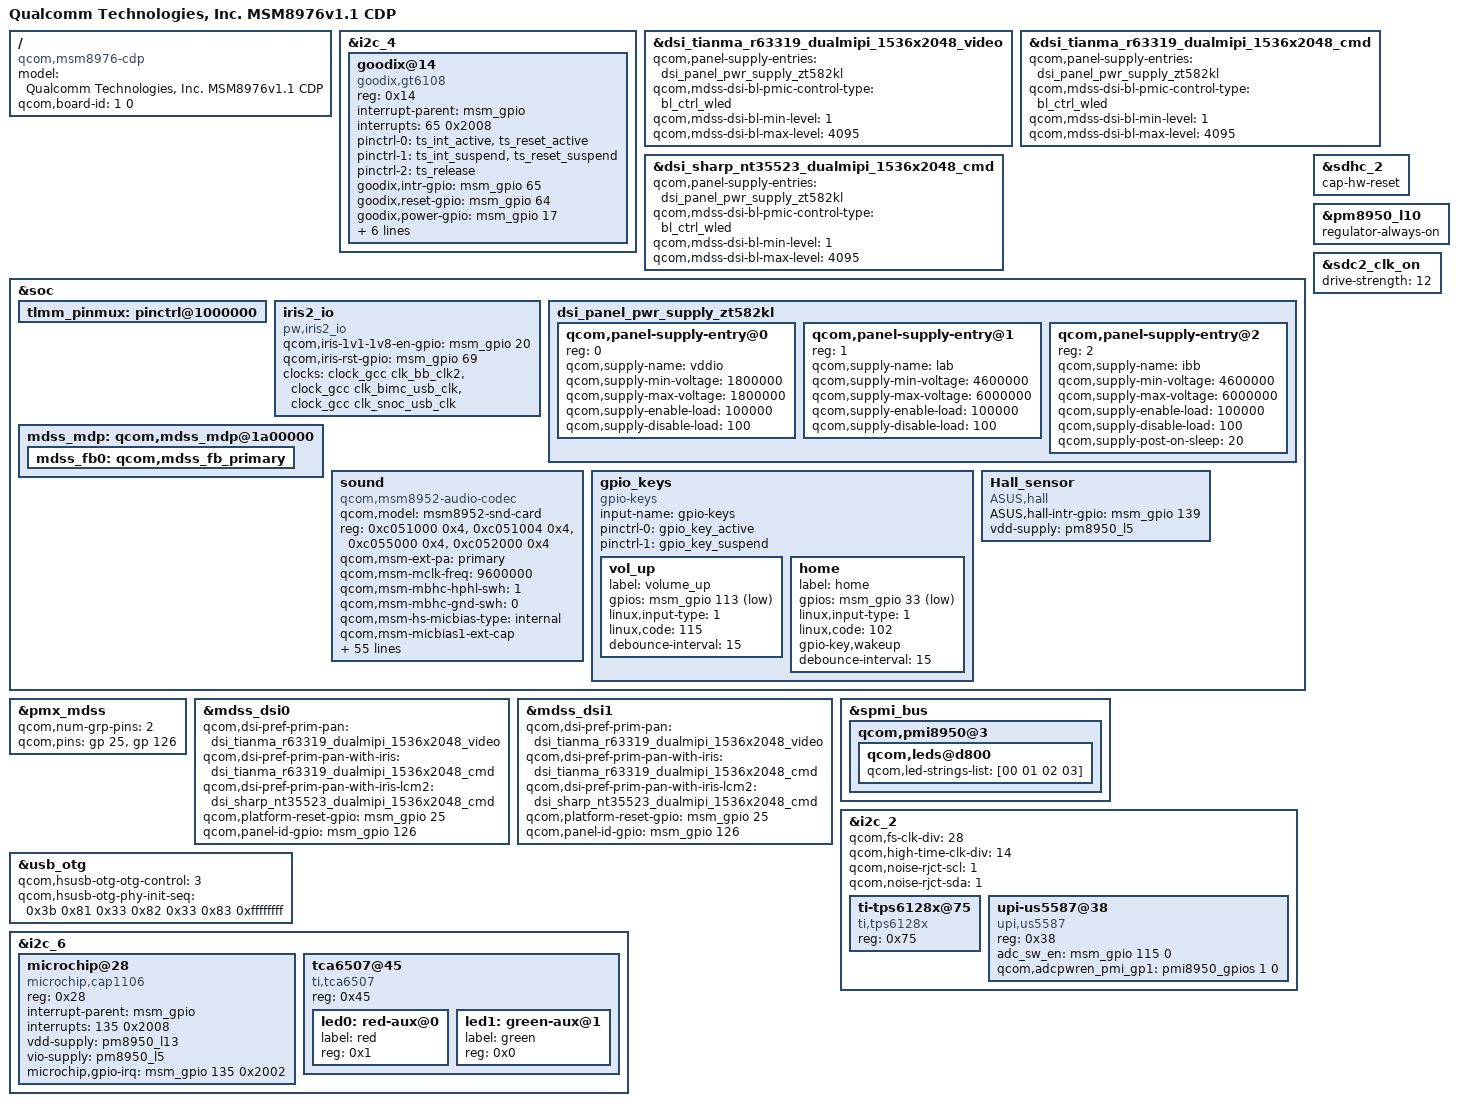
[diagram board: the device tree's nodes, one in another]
/*
 * Copyright (c) 2015, The Linux Foundation. All rights reserved.
 *
 * This program is free software; you can redistribute it and/or modify
 * it under the terms of the GNU General Public License version 2 and
 * only version 2 as published by the Free Software Foundation.
 *
 * This program is distributed in the hope that it will be useful,
 * but WITHOUT ANY WARRANTY; without even the implied warranty of
 * MERCHANTABILITY or FITNESS FOR A PARTICULAR PURPOSE.  See the
 * GNU General Public License for more details.
 */

/dts-v1/;

#include "msm8976-v1.1.dtsi"
#include "msm8976-cdp.dtsi"
#include "msm8976-camera-sensor-cdp-ZT582KL.dtsi"

/ {
	model = "Qualcomm Technologies, Inc. MSM8976v1.1 CDP";
	compatible = "qcom,msm8976-cdp", "qcom,msm8976", "qcom,cdp";
	qcom,board-id= <1 0>;
};

&i2c_4 { /* BLSP1 QUP4 */
	goodix@14 {
 		compatible = "goodix,gt6108";
		reg = <0x14>;
		interrupt-parent = <&msm_gpio>;
		interrupts = <65 0x2008>;
//		vdd-supply = <&pm8916_l17>;
//		vcc_i2c-supply = <&pm8916_l6>;
		/* pins used by touchscreen */
		pinctrl-names = "gt6108_init_default","gt6108_init_suspend";
		pinctrl-0 = <&ts_int_active &ts_reset_active>;
		pinctrl-1 = <&ts_int_suspend &ts_reset_suspend>;
		pinctrl-2 = <&ts_release>;
		goodix,intr-gpio = <&msm_gpio 65 0x2008>;
		goodix,reset-gpio = <&msm_gpio 64 0x0>;
		goodix,power-gpio = <&msm_gpio 17 0x0>;
		goodix,fw-name = "GD_Upgrade_App.i";
		goodix,display-coords = <0 0 1536 2048>;
		goodix,panel-coords = <0 0 1080 2000>;
		goodix,button-map= <70 150 907>;
		goodix,product-id = <6108>;
		goodix,i2c-pull-up;
	};
};

/* DISPLAY START*/

#include "dsi-panel-tianma-r63319-dualmipi-1536x2048-video.dtsi"
#include "dsi-panel-tianma-r63319-dualmipi-1536x2048-cmd.dtsi"
#include "dsi-panel-sharp-nt35523-dualmipi-1536x2048-cmd.dtsi"

&dsi_tianma_r63319_dualmipi_1536x2048_video {
/*  qcom,panel-supply-entries = <&dsi_panel_pwr_supply>;*/
    qcom,panel-supply-entries = <&dsi_panel_pwr_supply_zt582kl>;
    qcom,mdss-dsi-bl-pmic-control-type = "bl_ctrl_wled";
    qcom,mdss-dsi-bl-min-level = <1>;
    qcom,mdss-dsi-bl-max-level = <4095>;
/*  qcom,mdss-dsi-pan-enable-dynamic-fps;*/
/*  qcom,mdss-dsi-pan-fps-update = "dfps_immediate_porch_mode_hfp";*/
};

&dsi_tianma_r63319_dualmipi_1536x2048_cmd {
/*  qcom,panel-supply-entries = <&dsi_panel_pwr_supply>;*/
qcom,panel-supply-entries = <&dsi_panel_pwr_supply_zt582kl>;
qcom,mdss-dsi-bl-pmic-control-type = "bl_ctrl_wled";
qcom,mdss-dsi-bl-min-level = <1>;
qcom,mdss-dsi-bl-max-level = <4095>;
/*  qcom,mdss-dsi-pan-enable-dynamic-fps;*/
/*  qcom,mdss-dsi-pan-fps-update = "dfps_immediate_porch_mode_hfp";*/
};

&dsi_sharp_nt35523_dualmipi_1536x2048_cmd {
/*  qcom,panel-supply-entries = <&dsi_panel_pwr_supply>;*/
qcom,panel-supply-entries = <&dsi_panel_pwr_supply_zt582kl>;
qcom,mdss-dsi-bl-pmic-control-type = "bl_ctrl_wled";
qcom,mdss-dsi-bl-min-level = <1>;
qcom,mdss-dsi-bl-max-level = <4095>;
/*  qcom,mdss-dsi-pan-enable-dynamic-fps;*/
/*  qcom,mdss-dsi-pan-fps-update = "dfps_immediate_porch_mode_hfp";*/
};

&soc {
    tlmm_pinmux: pinctrl@1000000 {
        /delete-node/ pmx_nfc_reset;
        /delete-node/ tpiu_seta_14;
    };
};

&soc {
    iris2_io{
	 compatible = "pw,iris2_io";
	 qcom,iris-1v1-1v8-en-gpio = <&msm_gpio 20 0>;
	 qcom,iris-rst-gpio = <&msm_gpio 69 0>;
	 clocks = <&clock_gcc clk_bb_clk2>, <&clock_gcc clk_bimc_usb_clk>, <&clock_gcc clk_snoc_usb_clk>;
	 clock-names = "iris2_clk", "bimc_clk", "snoc_clk";
    };
};

&pmx_mdss {
    qcom,num-grp-pins = <2>;
    qcom,pins = <&gp 25>, <&gp 126>;
};

&mdss_dsi0 {
    qcom,dsi-pref-prim-pan = <&dsi_tianma_r63319_dualmipi_1536x2048_video>;
    qcom,dsi-pref-prim-pan-with-iris = <&dsi_tianma_r63319_dualmipi_1536x2048_cmd>;
    qcom,dsi-pref-prim-pan-with-iris-lcm2 = <&dsi_sharp_nt35523_dualmipi_1536x2048_cmd>;

    qcom,platform-reset-gpio = <&msm_gpio 25 0>;
    /delete-property/ qcom,platform-bklight-en-gpio;
    /delete-property/ qcom,panel-mode-gpio;
    qcom,panel-id-gpio = <&msm_gpio 126 0>;
};

&mdss_dsi1 {
    qcom,dsi-pref-prim-pan = <&dsi_tianma_r63319_dualmipi_1536x2048_video>;
    qcom,dsi-pref-prim-pan-with-iris = <&dsi_tianma_r63319_dualmipi_1536x2048_cmd>;
    qcom,dsi-pref-prim-pan-with-iris-lcm2 = <&dsi_sharp_nt35523_dualmipi_1536x2048_cmd>;

    qcom,platform-reset-gpio = <&msm_gpio 25 0>;
    /delete-property/ qcom,platform-bklight-en-gpio;
    /delete-property/ qcom,panel-mode-gpio;
    qcom,panel-id-gpio = <&msm_gpio 126 0>;
};

&spmi_bus{
    qcom,pmi8950@3 {
        qcom,leds@d800 {
            qcom,led-strings-list = [00 01 02 03];
        };
    };
};

&soc {
    dsi_panel_pwr_supply_zt582kl: dsi_panel_pwr_supply_zt582kl {
        #address-cells = <1>;
        #size-cells = <0>;

        qcom,panel-supply-entry@0 {
            reg = <0>;
            qcom,supply-name = "vddio";
            qcom,supply-min-voltage = <1800000>;
            qcom,supply-max-voltage = <1800000>;
            qcom,supply-enable-load = <100000>;
            qcom,supply-disable-load = <100>;
        };

        qcom,panel-supply-entry@1 {
            reg = <1>;
            qcom,supply-name = "lab";
            qcom,supply-min-voltage = <4600000>;
            qcom,supply-max-voltage = <6000000>;
            qcom,supply-enable-load = <100000>;
            qcom,supply-disable-load = <100>;
        };

        qcom,panel-supply-entry@2 {
            reg = <2>;
            qcom,supply-name = "ibb";
            qcom,supply-min-voltage = <4600000>;
            qcom,supply-max-voltage = <6000000>;
            qcom,supply-enable-load = <100000>;
            qcom,supply-disable-load = <100>;
            qcom,supply-post-on-sleep = <20>;
        };
    };

    mdss_mdp: qcom,mdss_mdp@1a00000 {
        mdss_fb0: qcom,mdss_fb_primary {
            /delete-property/ qcom,mdss-fb-splash-logo-enabled;
        };
    };
};

/* DISPLAY END*/

/* USB Start */
&i2c_2 {
       /* Override FS and HS divider to get SCL running at 400KHz. */
       qcom,fs-clk-div = <28>;
       qcom,high-time-clk-div = <14>;
       qcom,noise-rjct-scl = <1>;
       qcom,noise-rjct-sda = <1>;

       #include "rt1711-ZT582KL.dts"

    ti-tps6128x@75 {
        compatible = "ti,tps6128x";
        reg = <0x75>;
    };

    upi-us5587@38 {
        compatible = "upi,us5587";
        reg = <0x38>;
        adc_sw_en = <&msm_gpio 115 0>;
	 /*shilun*/
        qcom,adcpwren_pmi_gp1 = <&pmi8950_gpios 1 0>;
    };
};

&soc {
    /* delete unused node avoid use same gpio 19 for cc enb pin*/
    /delete-node/ pmx_i2c_8;
};

&usb_otg {
	 qcom,hsusb-otg-otg-control = <3>; /* USER control */
         qcom,hsusb-otg-phy-init-seq =
             <0x3b 0x81 0x33 0x82 0x33 0x83 0xffffffff>;
};

/* USB End */

/* AUDIO Start */

&soc {
    sound {
        compatible = "qcom,msm8952-audio-codec";
        qcom,model = "msm8952-snd-card";
        reg = <0xc051000 0x4>,
              <0xc051004 0x4>,
              <0xc055000 0x4>,
              <0xc052000 0x4>;
        reg-names = "csr_gp_io_mux_mic_ctl",
                    "csr_gp_io_mux_spkr_ctl",
                    "csr_gp_io_lpaif_pri_pcm_pri_mode_muxsel",
                    "csr_gp_io_mux_quin_ctl";

        qcom,msm-ext-pa = "primary";
        qcom,msm-mclk-freq = <9600000>;
        qcom,msm-mbhc-hphl-swh = <1>;
        qcom,msm-mbhc-gnd-swh = <0>;
        qcom,msm-hs-micbias-type = "internal";
        qcom,msm-micbias1-ext-cap;
        qcom,msm-micbias2-ext-cap;
        qcom,audio-routing =
                "RX_BIAS", "MCLK",
                "SPK_RX_BIAS", "MCLK",
                "INT_LDO_H", "MCLK",
                "MIC BIAS Internal1", "Handset Mic",
                "MIC BIAS Internal2", "Headset Mic",
                "MIC BIAS External", "Secondary Mic",
                "AMIC1", "MIC BIAS Internal1",
                "AMIC2", "MIC BIAS Internal2",
                "AMIC3", "MIC BIAS External",
		"DMIC1", "MIC BIAS Internal1",
                "MIC BIAS Internal1", "Digital Mic1",
                "DMIC2", "MIC BIAS Internal1",
                "MIC BIAS Internal1", "Digital Mic2",
                "WSA_SPK OUT", "VDD_WSA_SWITCH",
                "SpkrMono WSA_IN", "WSA_SPK OUT";
        qcom,msm-gpios =
                "pri_i2s";
        qcom,pinctrl-names =
                "all_off",
                "pri_i2s_act";
        pinctrl-names =
                "all_off",
                "pri_i2s_act";
        pinctrl-0 = <&cdc_pdm_lines_sus &cdc_pdm_lines_2_sus>;
        pinctrl-1 = <&cdc_pdm_lines_act &cdc_pdm_lines_2_act>;
        asoc-platform = <&pcm0>, <&pcm1>, <&pcm2>, <&voip>, <&voice>,
                        <&loopback>, <&compress>, <&hostless>,
                        <&afe>, <&lsm>, <&routing>, <&lpa>,
                        <&voice_svc>;
        asoc-platform-names = "msm-pcm-dsp.0", "msm-pcm-dsp.1",
                        "msm-pcm-dsp.2", "msm-voip-dsp",
                        "msm-pcm-voice", "msm-pcm-loopback",
                        "msm-compress-dsp", "msm-pcm-hostless",
                        "msm-pcm-afe", "msm-lsm-client",
                        "msm-pcm-routing", "msm-pcm-lpa",
                        "msm-voice-svc";
        asoc-cpu = <&dai_pri_auxpcm>, <&dai_hdmi>,
                        <&dai_mi2s0>, <&dai_mi2s1>, <&dai_mi2s2>,
                        <&dai_mi2s3>, <&dai_mi2s5>, <&dai_mi2s6>,
                        <&bt_sco_rx>, <&bt_sco_tx>, <&int_fm_rx>,
                        <&int_fm_tx>, <&afe_pcm_rx>, <&afe_pcm_tx>,
                        <&afe_proxy_rx>, <&afe_proxy_tx>,
                        <&incall_record_rx>, <&incall_record_tx>,
                        <&incall_music_rx>, <&incall_music_2_rx>;
        asoc-cpu-names = "msm-dai-q6-auxpcm.1", "msm-dai-q6-hdmi.8",
                        "msm-dai-q6-mi2s.0", "msm-dai-q6-mi2s.1",
                        "msm-dai-q6-mi2s.2", "msm-dai-q6-mi2s.3",
                        "msm-dai-q6-mi2s.5", "msm-dai-q6-mi2s.6",
                        /*
                        "msm-dai-q6-dev.16384", "msm-dai-q6-dev.16385",
                        "msm-dai-q6-dev.16386", "msm-dai-q6-dev.16387",
                        "msm-dai-q6-dev.16390", "msm-dai-q6-dev.16391",
                        "msm-dai-q6-dev.16392", "msm-dai-q6-dev.16393",
                        */
                        "msm-dai-q6-dev.12288", "msm-dai-q6-dev.12289",
                        "msm-dai-q6-dev.12292", "msm-dai-q6-dev.12293",
                        "msm-dai-q6-dev.224", "msm-dai-q6-dev.225",
                        "msm-dai-q6-dev.241", "msm-dai-q6-dev.240",
                        "msm-dai-q6-dev.32771", "msm-dai-q6-dev.32772",
                        "msm-dai-q6-dev.32773", "msm-dai-q6-dev.32770";
        asoc-codec = <&stub_codec>, <&pm8950_cajon_dig>;
        asoc-codec-names = "msm-stub-codec.1", "cajon_codec";

        msm-vdd-wsa-switch-supply = <&pm8950_l13>;
        qcom,msm-vdd-wsa-switch-voltage = <3075000>;
        qcom,msm-vdd-wsa-switch-current = <5000>;
        qcom,right-spk-amp = <&msm_gpio 62 0>;
	qcom,right-spk-5v = <&msm_gpio 55 0>;
    };
};

/* AUDIO End */

&soc {
    gpio_keys {
        compatible = "gpio-keys";
        input-name = "gpio-keys";
        pinctrl-names = "tlmm_gpio_key_active","tlmm_gpio_key_suspend";
        pinctrl-0 = <&gpio_key_active>;
        pinctrl-1 = <&gpio_key_suspend>;

        vol_up {
            label = "volume_up";
            gpios = <&msm_gpio 113 0x1>;
            linux,input-type = <1>;
            linux,code = <115>;
            debounce-interval = <15>;
        };

		home {
		    label = "home";
			gpios = <&msm_gpio 33 0x1>;
			linux,input-type = <1>;
			linux,code = <102>;
			gpio-key,wakeup;
			debounce-interval = <15>;
		};
   };
};

&soc{
        Hall_sensor {
                compatible = "ASUS,hall";
                ASUS,hall-intr-gpio = <&msm_gpio 139 0>;
                vdd-supply = <&pm8950_l5>;
        };
};

&sdhc_2 {
       /* apply hardware reset */
       cap-hw-reset;
};
/* Sensor Start */
&i2c_6 { /* BLSP2 QUP2 Cap Senosr */
	microchip@28 {
		compatible = "microchip,cap1106";
		reg = <0x28>;
		interrupt-parent = <&msm_gpio>;
		interrupts = <135 0x2008>;
		vdd-supply = <&pm8950_l13>;
		vio-supply = <&pm8950_l5>;
		/* pins used by touchscreen */
		microchip,gpio-irq = <&msm_gpio 135 0x2002>;
	};

	tca6507@45 {
		compatible = "ti,tca6507";
		#address-cells = <1>;
		#size-cells = <0>;
		reg = <0x45>;

		led0: red-aux@0 {
			label = "red";
			reg = <0x1>;
			/*linux,default-trigger = "default-on";*/
		};

		led1: green-aux@1 {
			label = "green";
			reg = <0x0>;
		};
	};
};
/* Sensor End */

/* set L10 always-on, since RT1715 need to keep alive at all time. */
&pm8950_l10 {
	regulator-always-on;
};

&sdc2_clk_on{
	drive-strength = <12>; /* 12 MA */
};

